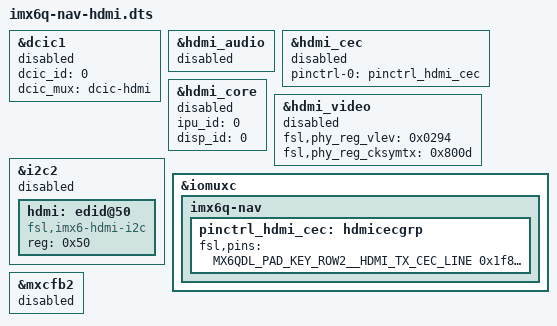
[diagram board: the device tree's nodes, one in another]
/*
 * Copyright 2015 Markus Niebel, TQ Systems GmbH
 *
 * The code contained herein is licensed under the GNU General Public
 * License. You may obtain a copy of the GNU General Public License
 * Version 2 or later at the following locations:
 *
 * http://www.opensource.org/licenses/gpl-license.html
 * http://www.gnu.org/copyleft/gpl.html
 */

#include "imx6q-nav.dts"

&dcic1 {
	dcic_id = <0>;
	dcic_mux = "dcic-hdmi";
	status = "disabled";
};

&hdmi_audio {
	status = "disabled";
};

&hdmi_cec {
	pinctrl-names = "default";
	pinctrl-0 = <&pinctrl_hdmi_cec>;
	status = "disabled";
};

&hdmi_core {
	ipu_id = <0>;
	disp_id = <0>;
	status = "disabled";
};

&hdmi_video {
	fsl,phy_reg_vlev = <0x0294>;
	fsl,phy_reg_cksymtx = <0x800d>;
	status = "disabled";
};

&i2c2 {
	status = "disabled";

	hdmi: edid@50 {
		compatible = "fsl,imx6-hdmi-i2c";
		reg = <0x50>;
	};
};

&iomuxc {
	imx6q-nav {
		pinctrl_hdmi_cec: hdmicecgrp {
			fsl,pins = <
				MX6QDL_PAD_KEY_ROW2__HDMI_TX_CEC_LINE 0x1f8b0
			>;
		};
	};
};

&mxcfb2 {
	status = "disabled";
};
